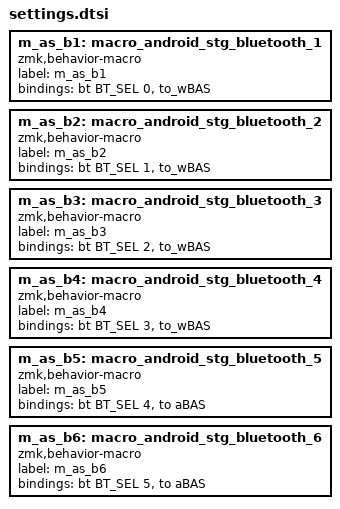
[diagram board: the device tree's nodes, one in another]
m_as_b1: macro_android_stg_bluetooth_1 {
    compatible = "zmk,behavior-macro";
    label = "m_as_b1";
    #binding-cells = <0>;
    bindings =
        <&bt BT_SEL 0 &to_wBAS>;
};

m_as_b2: macro_android_stg_bluetooth_2 {
    compatible = "zmk,behavior-macro";
    label = "m_as_b2";
    #binding-cells = <0>;
    bindings =
        <&bt BT_SEL 1 &to_wBAS>;
};

m_as_b3: macro_android_stg_bluetooth_3 {
    compatible = "zmk,behavior-macro";
    label = "m_as_b3";
    #binding-cells = <0>;
    bindings =
        <&bt BT_SEL 2 &to_wBAS>;
};

m_as_b4: macro_android_stg_bluetooth_4 {
    compatible = "zmk,behavior-macro";
    label = "m_as_b4";
    #binding-cells = <0>;
    bindings =
        <&bt BT_SEL 3 &to_wBAS>;
};

m_as_b5: macro_android_stg_bluetooth_5 {
    compatible = "zmk,behavior-macro";
    label = "m_as_b5";
    #binding-cells = <0>;
    bindings =
        <&bt BT_SEL 4 &to aBAS>;
};

m_as_b6: macro_android_stg_bluetooth_6 {
    compatible = "zmk,behavior-macro";
    label = "m_as_b6";
    #binding-cells = <0>;
    bindings =
        <&bt BT_SEL 5 &to aBAS>;
};
